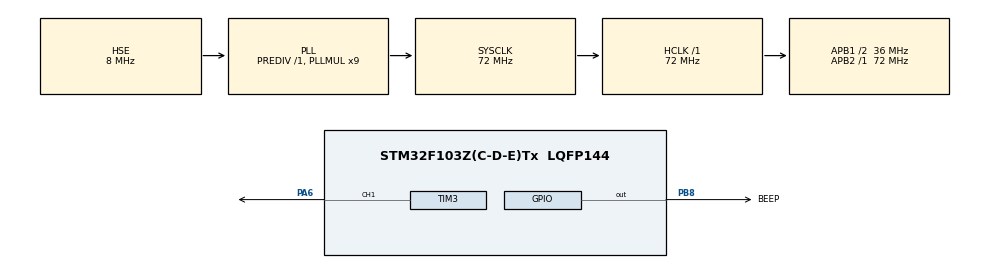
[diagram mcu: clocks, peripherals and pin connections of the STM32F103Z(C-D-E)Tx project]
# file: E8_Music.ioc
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Mcu.Family=STM32F1
Mcu.Name=STM32F103Z(C-D-E)Tx
Mcu.Package=LQFP144
NVIC.PriorityGroup=NVIC_PRIORITYGROUP_4
OSC_IN.Mode=HSE-External-Oscillator
OSC_IN.Signal=RCC_OSC_IN
OSC_OUT.Mode=HSE-External-Oscillator
OSC_OUT.Signal=RCC_OSC_OUT
PA13.Mode=Serial_Wire
PA13.Signal=SYS_JTMS-SWDIO
PA14.Mode=Serial_Wire
PA14.Signal=SYS_JTCK-SWCLK
PA6.Signal=S_TIM3_CH1
PB8.GPIO_Label=BEEP
PB8.GPIO_ModeDefaultOutputPP=GPIO_MODE_OUTPUT_PP
PB8.GPIO_PuPd=GPIO_PULLDOWN
PB8.GPIO_Speed=GPIO_SPEED_FREQ_HIGH
PB8.Signal=GPIO_Output
PC14-OSC32_IN.Mode=LSE-External-Oscillator
PC14-OSC32_IN.Signal=RCC_OSC32_IN
PC15-OSC32_OUT.Mode=LSE-External-Oscillator
PC15-OSC32_OUT.Signal=RCC_OSC32_OUT
ProjectManager.HeapSize=0x200
ProjectManager.StackSize=0x400
ProjectManager.TargetToolchain=MDK-ARM V5.32
RCC.AHBFreq_Value=72000000
RCC.APB1CLKDivider=RCC_HCLK_DIV2
RCC.APB1Freq_Value=36000000
RCC.APB1TimFreq_Value=72000000
RCC.APB2Freq_Value=72000000
RCC.APB2TimFreq_Value=72000000
RCC.HCLKFreq_Value=72000000
RCC.PLLMUL=RCC_PLL_MUL9
RCC.PLLSourceVirtual=RCC_PLLSOURCE_HSE
RCC.SYSCLKFreq_VALUE=72000000
RCC.SYSCLKSource=RCC_SYSCLKSOURCE_PLLCLK
RCC.USBFreq_Value=72000000
SH.S_TIM3_CH1.0=TIM3_CH1,PWM Generation1 CH1
TIM3.Channel-PWM\ Generation1\ CH1=TIM_CHANNEL_1
TIM3.Period=999
TIM3.Prescaler=71
VP_TIM3_VS_ClockSourceINT.Mode=Internal
board=custom

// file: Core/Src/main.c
/* USER CODE BEGIN Header */
/**
  ******************************************************************************
  * @file           : main.c
  * @brief          : Main program body
  ******************************************************************************
  * @attention
  *
  * Copyright (c) 2024 STMicroelectronics.
  * All rights reserved.
  *
  * This software is licensed under terms that can be found in the LICENSE file
  * in the root directory of this software component.
  * If no LICENSE file comes with this software, it is provided AS-IS.
  *
  ******************************************************************************
  */
/* USER CODE END Header */
#include "main.h"
#include "tim.h"
#include "gpio.h"

/* USER CODE BEGIN PD */
#define l_dao  262
#define l_re  294
#define l_mi  330
#define l_fa  349
#define l_suo  392
#define l_la  440
#define l_xi  494
#define dao  523
#define re  587
#define mi  659
#define fa  698
#define suo  784
#define la  880
#define xi  988
//功能为播放生日歌
/* USER CODE END PD */

/* USER CODE BEGIN PV */
const uint16_t notes[]=
{
l_suo,l_suo,l_la,l_suo,dao,l_xi,
l_suo,l_suo,l_la,l_suo,re,dao,
l_suo,l_suo,suo,mi,dao,l_la,
fa,fa,mi,dao,re,dao
};

const uint16_t time[]=
{
200,400,400,400,400,800,
200,400,400,400,400,800,
200,400,400,400,400,800,
200,200,400,400,400,800
};
/* USER CODE END PV */

void SystemClock_Config(void);
/* USER CODE BEGIN PFP */
void set_freq(uint32_t freq);
void happy_birthday_to_you(void);
/* USER CODE END PFP */

int main(void)
{

  /* MCU Configuration--------------------------------------------------------*/

  /* Reset of all peripherals, Initializes the Flash interface and the Systick. */
  HAL_Init();

  /* Configure the system clock */
  SystemClock_Config();

  /* Initialize all configured peripherals */
  MX_GPIO_Init();
  MX_TIM3_Init();
  /* USER CODE BEGIN 2 */
	HAL_TIM_PWM_Start(&htim3, TIM_CHANNEL_1);
  /* USER CODE END 2 */

  /* Infinite loop */
  while (1)
  {

    /* USER CODE BEGIN 3 */
		happy_birthday_to_you();
		HAL_Delay(2000);
  }
  /* USER CODE END 3 */
}

void SystemClock_Config(void)
{
  RCC_OscInitTypeDef RCC_OscInitStruct = {0};
  RCC_ClkInitTypeDef RCC_ClkInitStruct = {0};

  /** Initializes the RCC Oscillators according to the specified parameters
  * in the RCC_OscInitTypeDef structure.
  */
  RCC_OscInitStruct.OscillatorType = RCC_OSCILLATORTYPE_HSE;
  RCC_OscInitStruct.HSEState = RCC_HSE_ON;
  RCC_OscInitStruct.HSEPredivValue = RCC_HSE_PREDIV_DIV1;
  RCC_OscInitStruct.HSIState = RCC_HSI_ON;
  RCC_OscInitStruct.PLL.PLLState = RCC_PLL_ON;
  RCC_OscInitStruct.PLL.PLLSource = RCC_PLLSOURCE_HSE;
  RCC_OscInitStruct.PLL.PLLMUL = RCC_PLL_MUL9;
  if (HAL_RCC_OscConfig(&RCC_OscInitStruct) != HAL_OK)
  {
    Error_Handler();
  }

  /** Initializes the CPU, AHB and APB buses clocks
  */
  RCC_ClkInitStruct.ClockType = RCC_CLOCKTYPE_HCLK|RCC_CLOCKTYPE_SYSCLK
                              |RCC_CLOCKTYPE_PCLK1|RCC_CLOCKTYPE_PCLK2;
  RCC_ClkInitStruct.SYSCLKSource = RCC_SYSCLKSOURCE_PLLCLK;
  RCC_ClkInitStruct.AHBCLKDivider = RCC_SYSCLK_DIV1;
  RCC_ClkInitStruct.APB1CLKDivider = RCC_HCLK_DIV2;
  RCC_ClkInitStruct.APB2CLKDivider = RCC_HCLK_DIV1;

  if (HAL_RCC_ClockConfig(&RCC_ClkInitStruct, FLASH_LATENCY_2) != HAL_OK)
  {
    Error_Handler();
  }
}

/* USER CODE BEGIN 4 */
void set_freq(uint32_t freq)
{
    if(freq == 0) {
        HAL_TIM_PWM_Stop(&htim3, TIM_CHANNEL_1);
        return;
    }

    // 计时周期：72MHz / 72 / freq - 1
    uint32_t period = (1000000 / freq) - 1;
    __HAL_TIM_SET_AUTORELOAD(&htim3, period);
    __HAL_TIM_SET_COMPARE(&htim3, TIM_CHANNEL_1, period/2);  // 50%占空比
    HAL_TIM_PWM_Start(&htim3, TIM_CHANNEL_1);  //确保PWM重新启动
}

void happy_birthday_to_you(void)
{
    const int total_notes = sizeof(notes) / sizeof(notes[0]);
    int i=0;
    for(i=0;i<total_notes;i++)
    {
        set_freq(notes[i]);
        HAL_Delay(time[i]-20);  // 音符持续时间减去间隔时间
        set_freq(0);            // 设置频率为0来停止发声
        HAL_Delay(20);  // 音符间短暂停顿
    }
}
/* USER CODE END 4 */

void Error_Handler(void)
{
  __disable_irq();
  while (1)
  {
  }
}
